AUTOSAR XML (schema 00050)
package /ComponentTypes
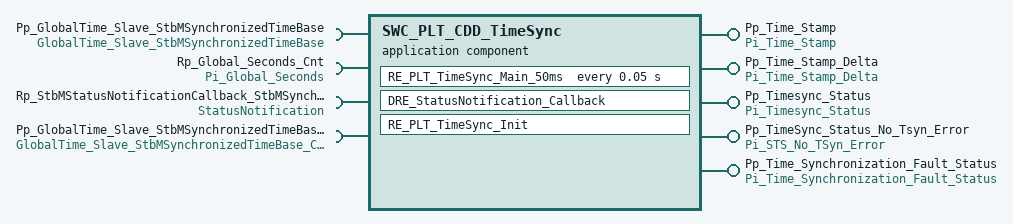
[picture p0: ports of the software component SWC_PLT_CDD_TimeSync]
  application sw component type SWC_PLT_CDD_TimeSync
    4 x provide port:
      Pp_Time_Stamp: nonqueued-sender-com-spec{data-element=De_StbM_TimeStampType, init-value=fields=[timeBaseStatus:0, nanoseconds:0, seconds:0, secondsHi:0]}, provided-interface=Pi_Time_Stamp
      Pp_Time_Stamp_Delta: nonqueued-sender-com-spec{data-element=De_Time_Stamp_Delta, init-value=0}, provided-interface=Pi_Time_Stamp_Delta
      Pp_Timesync_Status: nonqueued-sender-com-spec{data-element=De_Timesync_Status, init-value=85}, provided-interface=Pi_Timesync_Status
      Pp_TimeSync_Status_No_Tsyn_Error: nonqueued-sender-com-spec{data-element=De_STS_No_TSyn_Error, init-value=0}, provided-interface=Pi_STS_No_TSyn_Error
    require port Pp_GlobalTime_Slave_StbMSynchronizedTimeBase: required-com-specs=[GetCurrentTime, GetRateDeviation, GetTimeBaseStatus, GetTimeLeap, GetSyncTimeRecordHead], required-interface=GlobalTime_Slave_StbMSynchronizedTimeBase
    require port Rp_Global_Seconds_Cnt: nonqueued-receiver-com-spec{data-element=De_Global_Seconds_Cnt, filter=data-filter-type=ALWAYS, init-value=0}, required-interface=Pi_Global_Seconds
    require port Rp_StbMStatusNotificationCallback_StbMSynchronizedTimeBase: nonqueued-receiver-com-spec{data-element=eventNotification, filter=data-filter-type=ALWAYS}, required-interface=StatusNotification
    provide port Pp_Time_Synchronization_Fault_Status: nonqueued-sender-com-spec{data-element=De_Time_Synchronization_Fault_Status, init-value=170}, provided-interface=Pi_Time_Synchronization_Fault_Status
    require port Pp_GlobalTime_Slave_StbMSynchronizedTimeBase_CanTsync: required-com-specs=[GetSyncTimeRecordHead, GetTimeBaseStatus, GetTimeLeap, GetRateDeviation, GetCurrentTime], required-interface=GlobalTime_Slave_StbMSynchronizedTimeBase_CanTsync
    behavior SWC_PLT_CDD_TimeSync_InternalBehavior: handle-termination-and-restart=NO-SUPPORT
      exclusive area TimeSync_ExclusiveArea
      timing event TMT_RE_PLT_TimeSync_Main_50ms: start-on-event=RE_PLT_TimeSync_Main_50ms, period=0.05
      data received event DRT_DRE_StatusNotification_Callback_Rp_StbMStatusNotificationCallback_StbMSynchronizedTimeBase_eventNotification: start-on-event=DRE_StatusNotification_Callback, data=Rp_StbMStatusNotificationCallback_StbMSynchronizedTimeBase.eventNotification
      init event SWC_PLT_CDD_TimeSync_InitEvent: start-on-event=RE_PLT_TimeSync_Init
      runnable RE_PLT_TimeSync_Main_50ms: can-enters=TimeSync_ExclusiveArea
        data-receive-point-by-arguments:
          access REC_Rp_Global_Seconds_Cnt_De_Global_Seconds_Cnt: accessed-variable=Rp_Global_Seconds_Cnt.De_Global_Seconds_Cnt
          access REC_Rp_StbMStatusNotificationCallback_StbMSynchronizedTimeBase_eventNotification: accessed-variable=Rp_StbMStatusNotificationCallback_StbMSynchronizedTimeBase.eventNotification
        data-send-points:
          access SEND_Pp_Time_Stamp_De_StbM_TimeStampType: accessed-variable=Pp_Time_Stamp.De_StbM_TimeStampType
          access SEND_Pp_Timesync_Status_De_Timesync_Status: accessed-variable=Pp_Timesync_Status.De_Timesync_Status
          access SEND_Pp_Time_Synchronization_Fault_Status_De_Time_Synchronization_Fault_Status: accessed-variable=Pp_Time_Synchronization_Fault_Status.De_Time_Synchronization_Fault_Status
        10 x sync call:
          SC_Pp_GlobalTime_Slave_StbMSynchronizedTimeBase_GetCurrentTime: operation=Pp_GlobalTime_Slave_StbMSynchronizedTimeBase.GetCurrentTime
          SC_GlobalTime_Slave_StbMSynchronizedTimeBase_CanTsync_GetCurrentTime: operation=Pp_GlobalTime_Slave_StbMSynchronizedTimeBase_CanTsync.GetCurrentTime
          SC_GlobalTime_Slave_StbMSynchronizedTimeBase_CanTsync_GetRateDeviation: operation=Pp_GlobalTime_Slave_StbMSynchronizedTimeBase_CanTsync.GetRateDeviation
          SC_GlobalTime_Slave_StbMSynchronizedTimeBase_CanTsync_GetSyncTimeRecordHead: operation=Pp_GlobalTime_Slave_StbMSynchronizedTimeBase_CanTsync.GetSyncTimeRecordHead
          SC_GlobalTime_Slave_StbMSynchronizedTimeBase_CanTsync_GetTimeBaseStatus: operation=Pp_GlobalTime_Slave_StbMSynchronizedTimeBase_CanTsync.GetTimeBaseStatus
          SC_GlobalTime_Slave_StbMSynchronizedTimeBase_CanTsync_GetTimeLeap: operation=Pp_GlobalTime_Slave_StbMSynchronizedTimeBase_CanTsync.GetTimeLeap
          SC_Pp_GlobalTime_Slave_StbMSynchronizedTimeBase_GetRateDeviation: operation=Pp_GlobalTime_Slave_StbMSynchronizedTimeBase.GetRateDeviation
          SC_Pp_GlobalTime_Slave_StbMSynchronizedTimeBase_GetSyncTimeRecordHead: operation=Pp_GlobalTime_Slave_StbMSynchronizedTimeBase.GetSyncTimeRecordHead
          SC_Pp_GlobalTime_Slave_StbMSynchronizedTimeBase_GetTimeBaseStatus: operation=Pp_GlobalTime_Slave_StbMSynchronizedTimeBase.GetTimeBaseStatus
          SC_Pp_GlobalTime_Slave_StbMSynchronizedTimeBase_GetTimeLeap: operation=Pp_GlobalTime_Slave_StbMSynchronizedTimeBase.GetTimeLeap
      runnable DRE_StatusNotification_Callback
        data-receive-point-by-arguments:
          access REC_Rp_StbMStatusNotificationCallback_StbMSynchronizedTimeBase_eventNotification: accessed-variable=Rp_StbMStatusNotificationCallback_StbMSynchronizedTimeBase.eventNotification
        data-send-points:
          access SEND_Pp_TimeSync_Status_No_Tsyn_Error_De_STS_No_TSyn_Error: accessed-variable=Pp_TimeSync_Status_No_Tsyn_Error.De_STS_No_TSyn_Error
          access SEND_Pp_Time_Stamp_Delta_De_Time_Stamp_Delta: accessed-variable=Pp_Time_Stamp_Delta.De_Time_Stamp_Delta
      runnable RE_PLT_TimeSync_Init
  swc implementation SWC_PLT_CDD_TimeSync_Implementation: behavior=SWC_PLT_CDD_TimeSync_InternalBehavior
    code-descriptors:
      code Default: artifact-descriptors=autosar-engineering-object=category=SWSRC
